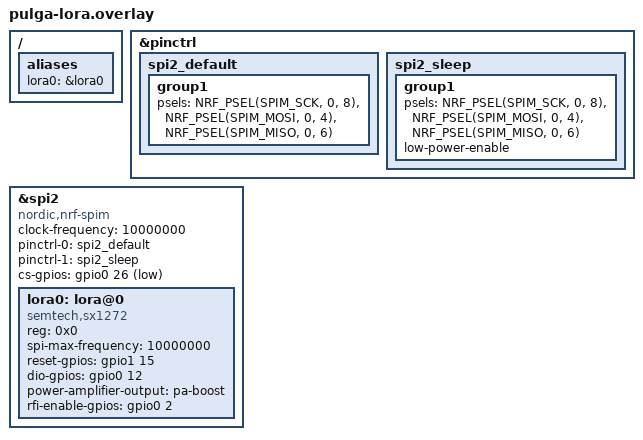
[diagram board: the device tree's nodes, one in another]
/*
 * Copyright (c) 2023 LSI-TEC
 *
 * SPDX-License-Identifier: Apache-2.0
 */

/ {
	aliases {
		lora0 = &lora0;
	};
};

&pinctrl {
	spi2_default: spi2_default {
		group1 {
			psels = <NRF_PSEL(SPIM_SCK, 0, 8)>,
					<NRF_PSEL(SPIM_MOSI, 0, 4)>,
					<NRF_PSEL(SPIM_MISO, 0, 6)>;
		};
	};

	spi2_sleep: spi2_sleep {
		group1 {
			psels = <NRF_PSEL(SPIM_SCK, 0, 8)>,
					<NRF_PSEL(SPIM_MOSI, 0, 4)>,
					<NRF_PSEL(SPIM_MISO, 0, 6)>;
			low-power-enable;
		};
	};
};

&spi2 {
	compatible = "nordic,nrf-spim";
	status = "okay";
	
	clock-frequency = <10000000>;
	pinctrl-0 = <&spi2_default>;
	pinctrl-1 = <&spi2_sleep>;
	pinctrl-names = "default", "sleep";
	
	cs-gpios = <&gpio0 26 GPIO_ACTIVE_LOW>;  /* P0.26 */
	
	lora0: lora@0 {
		compatible = "semtech,sx1272";
		reg = <0x0>;
		
		spi-max-frequency = <10000000>;
		reset-gpios = <&gpio1 15 GPIO_ACTIVE_HIGH>; /* P1.15 */
		dio-gpios = <&gpio0 12 (GPIO_PULL_DOWN | GPIO_ACTIVE_HIGH)>; /* P0.12 */
		power-amplifier-output = "pa-boost";
		rfi-enable-gpios = <&gpio0 2 GPIO_ACTIVE_HIGH>; /* P0.2 */
		
		status = "okay";
	};
};

